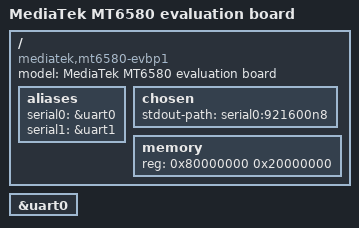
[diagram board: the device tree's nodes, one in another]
// SPDX-License-Identifier: GPL-2.0
/*
 * Copyright (c) 2015 MediaTek Inc.
 * Author: Mars.C <mars.cheng@mediatek.com>
 *
 */

/dts-v1/;
#include "mt6580.dtsi"

/ {
	model = "MediaTek MT6580 evaluation board";
	compatible = "mediatek,mt6580-evbp1", "mediatek,mt6580";

	aliases {
		serial0 = &uart0;
		serial1 = &uart1;
	};

	chosen {
		stdout-path = "serial0:921600n8";
	};

	memory {
		reg = <0x80000000 0x20000000>;
	};
};

&uart0 {
	status = "okay";
};
